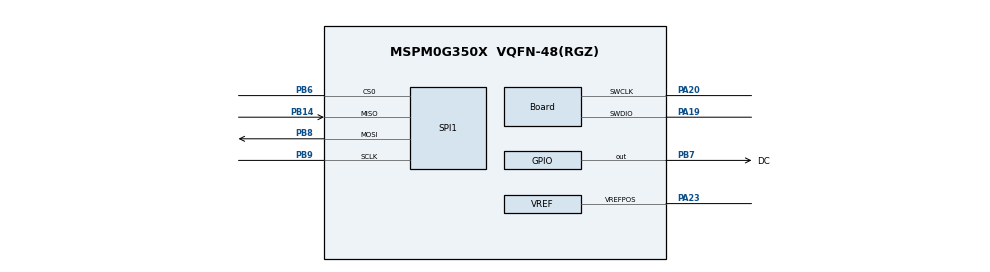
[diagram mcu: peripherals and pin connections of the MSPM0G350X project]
/**
 * @cliArgs --device "MSPM0G350X" --package "VQFN-48(RGZ)" --part "Default" --product "mspm0_sdk@1.20.01.06"
 * @versions {"tool":"1.18.1+3343"}
 */

/**
 * Import the modules used in this configuration.
 */
const ADC12         = scripting.addModule("/ti/driverlib/ADC12", {}, false);
const ADC121        = ADC12.addInstance();
const ADC122        = ADC12.addInstance();
const Board         = scripting.addModule("/ti/driverlib/Board");
const COMP          = scripting.addModule("/ti/driverlib/COMP", {}, false);
const COMP1         = COMP.addInstance();
const GPIO          = scripting.addModule("/ti/driverlib/GPIO", {}, false);
const GPIO1         = GPIO.addInstance();
const SPI           = scripting.addModule("/ti/driverlib/SPI", {}, false);
const SPI1          = SPI.addInstance();
const SYSCTL        = scripting.addModule("/ti/driverlib/SYSCTL");
const TIMER         = scripting.addModule("/ti/driverlib/TIMER", {}, false);
const TIMER1        = TIMER.addInstance();
const VREF          = scripting.addModule("/ti/driverlib/VREF");
const ProjectConfig = scripting.addModule("/ti/project_config/ProjectConfig");

/**
 * Write custom configuration values to the imported modules.
 */
const gate7  = system.clockTree["MFCLKGATE"];
gate7.enable = true;

const gate8  = system.clockTree["MFPCLKGATE"];
gate8.enable = true;

ADC121.$name               = "ADC12_0";
ADC121.repeatMode          = true;
ADC121.enabledInterrupts   = ["DL_ADC12_INTERRUPT_MEM0_RESULT_LOADED"];
ADC121.adcMem0vref         = "VREF";
ADC121.sampleTime0         = "195.3125us";
ADC121.sampClkDiv          = "DL_ADC12_CLOCK_DIVIDE_8";
ADC121.peripheral.$assign  = "ADC0";
ADC121.adcPin0Config.$name = "ti_driverlib_gpio_GPIOPinGeneric7";

ADC122.$name               = "ADC12_1";
ADC122.startAdd            = 1;
ADC122.repeatMode          = true;
ADC122.adcMem1vref         = "VREF";
ADC122.enabledInterrupts   = ["DL_ADC12_INTERRUPT_MEM1_RESULT_LOADED"];
ADC122.adcMem1chansel      = "DL_ADC12_INPUT_CHAN_3";
ADC122.sampleTime0         = "195.3125us";
ADC122.sampClkDiv          = "DL_ADC12_CLOCK_DIVIDE_8";
ADC122.peripheral.$assign  = "ADC1";
ADC122.adcPin3Config.$name = "ti_driverlib_gpio_GPIOPinGeneric10";

Board.peripheral.$assign          = "DEBUGSS";
Board.peripheral.swclkPin.$assign = "PA20";
Board.peripheral.swdioPin.$assign = "PA19";

COMP1.$name          = "COMP_0";
COMP1.hysteresis     = "DL_COMP_HYSTERESIS_20";
COMP1.terminalSelect = "DL_COMP_REF_TERMINAL_SELECT_NEG";
COMP1.controlSelect  = "DL_COMP_DAC_CONTROL_SW";
COMP1.setDACCode0    = 0x80;
COMP1.vSource        = "DL_COMP_REF_SOURCE_VDDA_DAC";

GPIO1.$name                         = "OLED";
GPIO1.associatedPins[0].$name       = "DC";
GPIO1.associatedPins[0].assignedPin = "7";
GPIO1.associatedPins[0].pin.$assign = "PB7";

SPI1.$name                      = "SPI_0";
SPI1.peripheral.$assign         = "SPI1";
SPI1.peripheral.sclkPin.$assign = "PB9";
SPI1.peripheral.mosiPin.$assign = "PB8";
SPI1.peripheral.misoPin.$assign = "PB14";
SPI1.peripheral.cs0Pin.$assign  = "PB6";
SPI1.sclkPinConfig.$name        = "ti_driverlib_gpio_GPIOPinGeneric0";
SPI1.mosiPinConfig.$name        = "ti_driverlib_gpio_GPIOPinGeneric1";
SPI1.misoPinConfig.$name        = "ti_driverlib_gpio_GPIOPinGeneric2";
SPI1.cs0PinConfig.$name         = "ti_driverlib_gpio_GPIOPinGeneric6";

SYSCTL.MFCLKEn     = true;
SYSCTL.MFPCLKEn    = true;
SYSCTL.clockTreeEn = true;

TIMER1.$name              = "TIMER_0";
TIMER1.timerMode          = "PERIODIC";
TIMER1.timerStartTimer    = true;
TIMER1.timerClkSrc        = "MFCLK";
TIMER1.timerClkDiv        = 8;
TIMER1.timerClkPrescale   = 8;
TIMER1.timerPeriod        = "1000 ms";
TIMER1.interrupts         = ["ZERO"];
TIMER1.peripheral.$assign = "TIMA0";

VREF.basicIntVolt                  = "DL_VREF_BUFCONFIG_OUTPUT_2_5V";
VREF.checkVREFReady                = true;
VREF.basicExtVolt                  = 3.3;
VREF.advClockConfigEnable          = true;
VREF.basicMode                     = "DL_VREF_ENABLE_DISABLE";
VREF.peripheral.$assign            = "VREF";
VREF.peripheral.vrefPosPin.$assign = "PA23";
VREF.vrefPosPinConfig.$name        = "ti_driverlib_gpio_GPIOPinGeneric9";

ProjectConfig.deviceSpin = "MSPM0G3507";

/**
 * Pinmux solution for unlocked pins/peripherals. This ensures that minor changes to the automatic solver in a future
 * version of the tool will not impact the pinmux you originally saw.  These lines can be completely deleted in order to
 * re-solve from scratch.
 */
ADC121.peripheral.adcPin0.$suggestSolution = "PA27";
ADC122.peripheral.adcPin3.$suggestSolution = "PA18";
COMP1.peripheral.$suggestSolution          = "COMP0";
